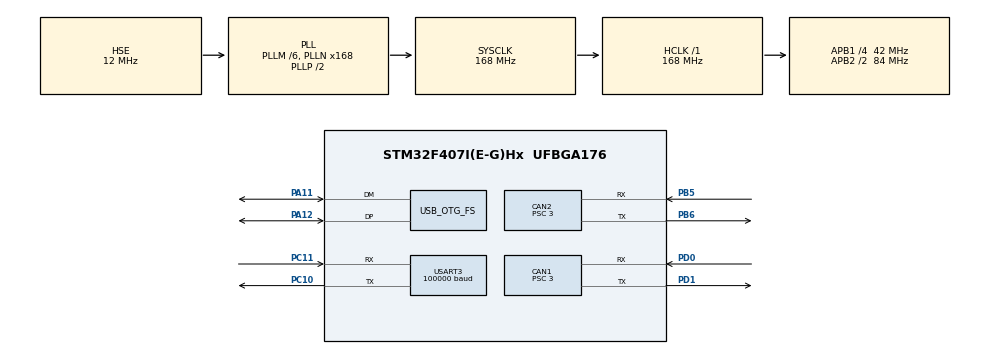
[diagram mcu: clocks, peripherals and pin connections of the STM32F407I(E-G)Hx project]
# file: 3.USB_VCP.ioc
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CAN1.AWUM=ENABLE
CAN1.BS1=CAN_BS1_10TQ
CAN1.BS2=CAN_BS2_3TQ
CAN1.CalculateBaudRate=1000000
CAN1.CalculateTimeBit=1000
CAN1.CalculateTimeQuantum=71.42857142857143
CAN1.NART=ENABLE
CAN1.Prescaler=3
CAN2.AWUM=ENABLE
CAN2.BS1=CAN_BS1_10TQ
CAN2.BS2=CAN_BS2_3TQ
CAN2.CalculateBaudRate=1000000
CAN2.CalculateTimeBit=1000
CAN2.CalculateTimeQuantum=71.42857142857143
CAN2.NART=ENABLE
CAN2.Prescaler=3
Dma.Request0=USART3_RX
Dma.USART3_RX.0.Direction=DMA_PERIPH_TO_MEMORY
Dma.USART3_RX.0.FIFOMode=DMA_FIFOMODE_DISABLE
Dma.USART3_RX.0.Instance=DMA1_Stream1
Dma.USART3_RX.0.MemDataAlignment=DMA_MDATAALIGN_BYTE
Dma.USART3_RX.0.MemInc=DMA_MINC_ENABLE
Dma.USART3_RX.0.Mode=DMA_CIRCULAR
Dma.USART3_RX.0.PeriphDataAlignment=DMA_PDATAALIGN_BYTE
Dma.USART3_RX.0.PeriphInc=DMA_PINC_DISABLE
Dma.USART3_RX.0.Priority=DMA_PRIORITY_VERY_HIGH
FREERTOS.INCLUDE_vTaskDelayUntil=1
FREERTOS.Tasks01=defaultTask,0,128,StartDefaultTask,Default,NULL,Dynamic,NULL,NULL;USB_task,1,512,USB_Task,As weak,NULL,Dynamic,NULL,NULL;MotorTask,1,512,Motor_Task,As weak,NULL,Dynamic,NULL,NULL
FREERTOS.configUSE_NEWLIB_REENTRANT=1
Mcu.Family=STM32F4
Mcu.Name=STM32F407I(E-G)Hx
Mcu.Package=UFBGA176
NVIC.CAN1_RX0_IRQn=true\:5\:0\:true\:false\:true\:true\:true\:true\:true
NVIC.CAN2_RX1_IRQn=true\:5\:0\:false\:false\:true\:true\:true\:true\:true
NVIC.DMA1_Stream1_IRQn=true\:5\:0\:false\:false\:true\:true\:false\:true\:true
NVIC.OTG_FS_IRQn=true\:5\:0\:false\:false\:true\:true\:false\:true\:true
NVIC.PriorityGroup=NVIC_PRIORITYGROUP_4
NVIC.TIM8_TRG_COM_TIM14_IRQn=true\:15\:0\:false\:false\:true\:false\:false\:true\:true
NVIC.TimeBase=TIM8_TRG_COM_TIM14_IRQn
NVIC.TimeBaseIP=TIM14
NVIC.USART3_IRQn=true\:5\:0\:false\:false\:true\:true\:true\:true\:true
PA11.Mode=Device_Only
PA11.Signal=USB_OTG_FS_DM
PA12.GPIO_PuPd=GPIO_PULLDOWN
PA12.Mode=Device_Only
PA12.Signal=USB_OTG_FS_DP
PA13.Mode=Serial_Wire
PA13.Signal=SYS_JTMS-SWDIO
PA14.Mode=Serial_Wire
PA14.Signal=SYS_JTCK-SWCLK
PB5.Mode=CAN_Activate
PB5.Signal=CAN2_RX
PB6.Mode=CAN_Activate
PB6.Signal=CAN2_TX
PC10.Mode=Asynchronous
PC10.Signal=USART3_TX
PC11.Mode=Asynchronous
PC11.Signal=USART3_RX
PC14-OSC32_IN.Mode=LSE-External-Oscillator
PC14-OSC32_IN.Signal=RCC_OSC32_IN
PC15-OSC32_OUT.Mode=LSE-External-Oscillator
PC15-OSC32_OUT.Signal=RCC_OSC32_OUT
PD0.Mode=CAN_Activate
PD0.Signal=CAN1_RX
PD1.Mode=CAN_Activate
PD1.Signal=CAN1_TX
PH0-OSC_IN.Mode=HSE-External-Oscillator
PH0-OSC_IN.Signal=RCC_OSC_IN
PH1-OSC_OUT.Mode=HSE-External-Oscillator
PH1-OSC_OUT.Signal=RCC_OSC_OUT
ProjectManager.HeapSize=0x400
ProjectManager.StackSize=0x2000
ProjectManager.TargetToolchain=STM32CubeIDE
RCC.48MHZClocksFreq_Value=48000000
RCC.AHBFreq_Value=168000000
RCC.APB1CLKDivider=RCC_HCLK_DIV4
RCC.APB1Freq_Value=42000000
RCC.APB1TimFreq_Value=84000000
RCC.APB2CLKDivider=RCC_HCLK_DIV2
RCC.APB2Freq_Value=84000000
RCC.APB2TimFreq_Value=168000000
RCC.CortexFreq_Value=168000000
RCC.HCLKFreq_Value=168000000
RCC.HSE_VALUE=12000000
RCC.HSI_VALUE=16000000
RCC.PLLM=6
RCC.PLLN=168
RCC.PLLQ=7
RCC.SYSCLKFreq_VALUE=168000000
RCC.SYSCLKSource=RCC_SYSCLKSOURCE_PLLCLK
RCC.VCOOutputFreq_Value=336000000
USART3.BaudRate=100000
USART3.Parity=PARITY_EVEN
USART3.VirtualMode=VM_ASYNC
USART3.WordLength=WORDLENGTH_9B
USB_DEVICE.CLASS_NAME_FS=CDC
USB_DEVICE.MANUFACTURER_STRING-CDC_FS=Ciallo~
USB_DEVICE.VirtualMode-CDC_FS=Cdc
USB_DEVICE.VirtualModeFS=Cdc_FS
USB_OTG_FS.Sof_enable=DISABLE
USB_OTG_FS.VirtualMode=Device_Only
VP_FREERTOS_VS_CMSIS_V1.Mode=CMSIS_V1
VP_SYS_VS_tim14.Mode=TIM14
VP_USB_DEVICE_VS_USB_DEVICE_CDC_FS.Mode=CDC_FS
board=custom

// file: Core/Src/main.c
/* USER CODE BEGIN Header */
/**
  ******************************************************************************
  * @file           : main.c
  * @brief          : Main program body
  ******************************************************************************
  * @attention
  *
  * Copyright (c) 2025 STMicroelectronics.
  * All rights reserved.
  *
  * This software is licensed under terms that can be found in the LICENSE file
  * in the root directory of this software component.
  * If no LICENSE file comes with this software, it is provided AS-IS.
  *
  ******************************************************************************
  */
/* USER CODE END Header */
#include "main.h"
#include "cmsis_os.h"
#include "can.h"
#include "dma.h"
#include "usart.h"
#include "usb_device.h"
#include "gpio.h"

/* USER CODE BEGIN Includes */
#include "Middleware_CAN.h"
#include "Device_GM6020.h"
#include "DR16_Remote.hpp"
/* USER CODE END Includes */

/* USER CODE BEGIN PD */
uint8_t RC_Data[18];
RC_t RC;
/* USER CODE END PD */

void SystemClock_Config(void);
void MX_FREERTOS_Init(void);
/* USER CODE BEGIN PFP */
// void HAL_CAN_RxFifo0MsgPendingCallback(CAN_HandleTypeDef * hcan) {
//     CAN_Rx_Data(&hcan1);
//     GM6020_update();
// }
/* USER CODE END PFP */

int main(void)
{

  /* MCU Configuration--------------------------------------------------------*/

  /* Reset of all peripherals, Initializes the Flash interface and the Systick. */
  HAL_Init();

  /* Configure the system clock */
  SystemClock_Config();

  /* Initialize all configured peripherals */
  MX_GPIO_Init();
  MX_DMA_Init();
  MX_CAN1_Init();
  MX_CAN2_Init();
  MX_USART3_UART_Init();
  /* USER CODE BEGIN 2 */
  CAN_Init(&hcan1);
  CAN_Init(&hcan2);
  /* USER CODE END 2 */

  /* Call init function for freertos objects (in cmsis_os2.c) */
  MX_FREERTOS_Init();

  /* Start scheduler */
  osKernelStart();

  /* We should never get here as control is now taken by the scheduler */

  /* Infinite loop */
  while (1)
  {

  }
}

void SystemClock_Config(void)
{
  RCC_OscInitTypeDef RCC_OscInitStruct = {0};
  RCC_ClkInitTypeDef RCC_ClkInitStruct = {0};

  /** Configure the main internal regulator output voltage
  */
  __HAL_RCC_PWR_CLK_ENABLE();
  __HAL_PWR_VOLTAGESCALING_CONFIG(PWR_REGULATOR_VOLTAGE_SCALE1);

  /** Initializes the RCC Oscillators according to the specified parameters
  * in the RCC_OscInitTypeDef structure.
  */
  RCC_OscInitStruct.OscillatorType = RCC_OSCILLATORTYPE_HSE;
  RCC_OscInitStruct.HSEState = RCC_HSE_ON;
  RCC_OscInitStruct.PLL.PLLState = RCC_PLL_ON;
  RCC_OscInitStruct.PLL.PLLSource = RCC_PLLSOURCE_HSE;
  RCC_OscInitStruct.PLL.PLLM = 6;
  RCC_OscInitStruct.PLL.PLLN = 168;
  RCC_OscInitStruct.PLL.PLLP = RCC_PLLP_DIV2;
  RCC_OscInitStruct.PLL.PLLQ = 7;
  if (HAL_RCC_OscConfig(&RCC_OscInitStruct) != HAL_OK)
  {
    Error_Handler();
  }

  /** Initializes the CPU, AHB and APB buses clocks
  */
  RCC_ClkInitStruct.ClockType = RCC_CLOCKTYPE_HCLK|RCC_CLOCKTYPE_SYSCLK
                              |RCC_CLOCKTYPE_PCLK1|RCC_CLOCKTYPE_PCLK2;
  RCC_ClkInitStruct.SYSCLKSource = RCC_SYSCLKSOURCE_PLLCLK;
  RCC_ClkInitStruct.AHBCLKDivider = RCC_SYSCLK_DIV1;
  RCC_ClkInitStruct.APB1CLKDivider = RCC_HCLK_DIV4;
  RCC_ClkInitStruct.APB2CLKDivider = RCC_HCLK_DIV2;

  if (HAL_RCC_ClockConfig(&RCC_ClkInitStruct, FLASH_LATENCY_5) != HAL_OK)
  {
    Error_Handler();
  }
}

void HAL_TIM_PeriodElapsedCallback(TIM_HandleTypeDef *htim)
{
  if (htim->Instance == TIM14) {
    HAL_IncTick();
  }
}

void Error_Handler(void)
{
  __disable_irq();
  while (1)
  {
  }
}

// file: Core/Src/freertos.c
/* USER CODE BEGIN Header */
/**
  ******************************************************************************
  * File Name          : freertos.c
  * Description        : Code for freertos applications
  ******************************************************************************
  * @attention
  *
  * Copyright (c) 2025 STMicroelectronics.
  * All rights reserved.
  *
  * This software is licensed under terms that can be found in the LICENSE file
  * in the root directory of this software component.
  * If no LICENSE file comes with this software, it is provided AS-IS.
  *
  ******************************************************************************
  */
/* USER CODE END Header */

#include "FreeRTOS.h"
#include "task.h"
#include "main.h"
#include "cmsis_os.h"

osThreadId defaultTaskHandle;
osThreadId USB_taskHandle;
osThreadId MotorTaskHandle;

void StartDefaultTask(void const * argument);
void USB_Task(void const * argument);
void Motor_Task(void const * argument);

extern void MX_USB_DEVICE_Init(void);
void MX_FREERTOS_Init(void); /* (MISRA C 2004 rule 8.1) */

/* GetIdleTaskMemory prototype (linked to static allocation support) */
void vApplicationGetIdleTaskMemory( StaticTask_t **ppxIdleTaskTCBBuffer, StackType_t **ppxIdleTaskStackBuffer, uint32_t *pulIdleTaskStackSize );

/* USER CODE BEGIN GET_IDLE_TASK_MEMORY */
static StaticTask_t xIdleTaskTCBBuffer;
static StackType_t xIdleStack[configMINIMAL_STACK_SIZE];

void vApplicationGetIdleTaskMemory( StaticTask_t **ppxIdleTaskTCBBuffer, StackType_t **ppxIdleTaskStackBuffer, uint32_t *pulIdleTaskStackSize )
{
  *ppxIdleTaskTCBBuffer = &xIdleTaskTCBBuffer;
  *ppxIdleTaskStackBuffer = &xIdleStack[0];
  *pulIdleTaskStackSize = configMINIMAL_STACK_SIZE;
  /* place for user code */
}
/* USER CODE END GET_IDLE_TASK_MEMORY */

void MX_FREERTOS_Init(void) {

  /* Create the thread(s) */
  /* definition and creation of defaultTask */
  osThreadDef(defaultTask, StartDefaultTask, osPriorityNormal, 0, 128);
  defaultTaskHandle = osThreadCreate(osThread(defaultTask), NULL);

  /* definition and creation of USB_task */
  osThreadDef(USB_task, USB_Task, osPriorityAboveNormal, 0, 512);
  USB_taskHandle = osThreadCreate(osThread(USB_task), NULL);

  /* definition and creation of MotorTask */
  osThreadDef(MotorTask, Motor_Task, osPriorityAboveNormal, 0, 512);
  MotorTaskHandle = osThreadCreate(osThread(MotorTask), NULL);

}

void StartDefaultTask(void const * argument)
{
  /* init code for USB_DEVICE */
  MX_USB_DEVICE_Init();
  for(;;)
  {
    osDelay(1);
  }
}

__weak void USB_Task(void const * argument)
{
  for(;;)
  {
    osDelay(1);
  }
}

__weak void Motor_Task(void const * argument)
{
  for(;;)
  {
    osDelay(1);
  }
}
